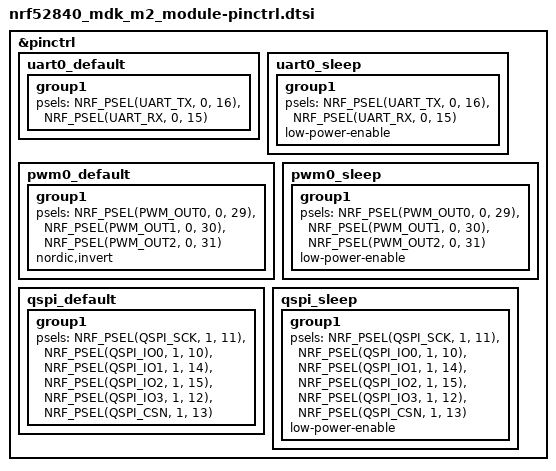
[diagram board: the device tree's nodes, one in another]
/*
 * Copyright (c) 2022 Nordic Semiconductor
 * SPDX-License-Identifier: Apache-2.0
 */

&pinctrl {
	uart0_default: uart0_default {
		group1 {
			psels = <NRF_PSEL(UART_TX, 0, 16)>,
			        <NRF_PSEL(UART_RX, 0, 15)>;
		};
	};

	uart0_sleep: uart0_sleep {
		group1 {
			psels = <NRF_PSEL(UART_TX, 0, 16)>,
			        <NRF_PSEL(UART_RX, 0, 15)>;
			low-power-enable;
		};
	};

	pwm0_default: pwm0_default {
		group1 {
			psels = <NRF_PSEL(PWM_OUT0, 0, 29)>,
			        <NRF_PSEL(PWM_OUT1, 0, 30)>,
			        <NRF_PSEL(PWM_OUT2, 0, 31)>;
			nordic,invert;
		};
	};

	pwm0_sleep: pwm0_sleep {
		group1 {
			psels = <NRF_PSEL(PWM_OUT0, 0, 29)>,
			        <NRF_PSEL(PWM_OUT1, 0, 30)>,
			        <NRF_PSEL(PWM_OUT2, 0, 31)>;
			low-power-enable;
		};
	};

	qspi_default: qspi_default {
		group1 {
			psels = <NRF_PSEL(QSPI_SCK, 1, 11)>,
			        <NRF_PSEL(QSPI_IO0, 1, 10)>,
			        <NRF_PSEL(QSPI_IO1, 1, 14)>,
			        <NRF_PSEL(QSPI_IO2, 1, 15)>,
			        <NRF_PSEL(QSPI_IO3, 1, 12)>,
			        <NRF_PSEL(QSPI_CSN, 1, 13)>;
		};
	};

	qspi_sleep: qspi_sleep {
		group1 {
			psels = <NRF_PSEL(QSPI_SCK, 1, 11)>,
			        <NRF_PSEL(QSPI_IO0, 1, 10)>,
			        <NRF_PSEL(QSPI_IO1, 1, 14)>,
			        <NRF_PSEL(QSPI_IO2, 1, 15)>,
			        <NRF_PSEL(QSPI_IO3, 1, 12)>,
			        <NRF_PSEL(QSPI_CSN, 1, 13)>;
			low-power-enable;
		};
	};
};
